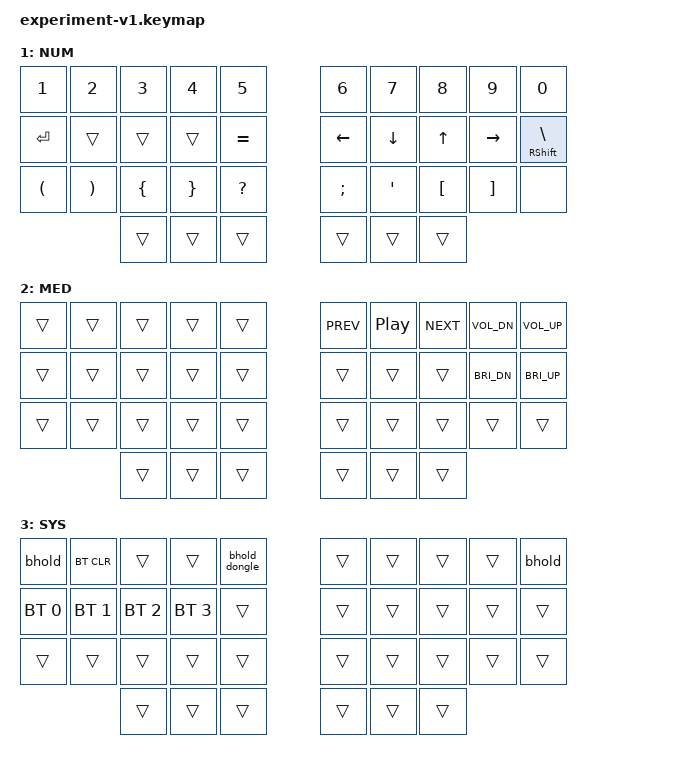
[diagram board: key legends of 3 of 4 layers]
#include <behaviors.dtsi>
#include <dt-bindings/zmk/keys.h>
#include <dt-bindings/zmk/bt.h>
#include <dt-bindings/zmk/outputs.h>

// Home row mods macro
#define HRML(k1,k2,k3,k4) &hml LSHFT k1 &hml LCTRL k2  &hml LALT k3  &hml LGUI k4
#define HRMR(k1,k2,k3,k4) &hmr RGUI k1  &hmr RALT k2  &hmr RCTRL k3  &hmr RSHFT k4

// Key positions for positional hold-tap, kept for reference. Currently unused:
// the homerow mods below deliberately do NOT use cross-hand gating (see the
// note on `hml`). This board is a TOTEMIST (36 keys), so these match the
// standard 36-key numbering -- see the matrix transform in
// config/boards/shields/totem/totem.dtsi:
//   Row 0:     0  1  2  3  4  |  5  6  7  8  9
//   Row 1:    10 11 12 13 14  | 15 16 17 18 19
//   Row 2:    20 21 22 23 24  | 25 26 27 28 29
//   Thumbs:      30 31 32     | 33 34 35
#define KEYS_L 0 1 2 3 4 10 11 12 13 14 20 21 22 23 24   // left-hand keys
#define KEYS_R 5 6 7 8 9 15 16 17 18 19 25 26 27 28 29   // right-hand keys
#define THUMBS 30 31 32 33 34 35                         // thumb keys

#define L0 0
#define L1 1
#define L2 2
#define L3 3

// Layer-tap, used by the left Enter/L1 and right Space/L1 thumbs.
//
// ZMK's stock `&lt` is `tap-preferred`, which only resolves a hold when the
// tapping term expires -- pressing and releasing another key while it is held
// does NOT trigger the hold. So a quick layer chord (hold the thumb, tap a
// key, release) completed inside 200ms emits SPACE plus that key instead of
// the layer keycode. `balanced` resolves the hold as soon as another key is
// pressed and released, which is exactly what a layer chord looks like.
&lt {
    flavor = "balanced";
    tapping-term-ms = <175>;
    quick-tap-ms = <125>;
};

/ {
    behaviors {
        // Grave/Shift and Tab/Shift on the left; minus/GUI on the right.
        //
        // Deliberately has NO `global-quick-tap` / `require-prior-idle-ms`.
        // Those make ZMK resolve the key to an *instant tap* whenever any other
        // key was pressed within the preceding window, no matter how long or
        // how hard the key is then held -- see is_quick_tap() in ZMK's
        // behavior_hold_tap.c. Since Shift is nearly always pressed immediately
        // after typing a letter, that reliably emitted TAB instead of SHIFT.
        //
        // Prior-idle gating is right for homerow mods (see hml/hmr below), but
        // wrong for thumbs, which are never pressed accidentally while typing.
        ht: hold_tap {
            label = "hold_tap";
            compatible = "zmk,behavior-hold-tap";
            #binding-cells = <2>;
            flavor = "balanced";
            tapping-term-ms = <175>;
            quick-tap-ms = <125>;
            bindings = <&kp>, <&kp>;
        };

        // Homerow mods.
        //
        // These are split out from the thumb `ht` behavior so the two can be
        // tuned independently. Timing was 220ms / prior-idle 150ms; it is now
        // 190ms / 100ms to bias toward HOLD, since missed holds proved far
        // more common than false ones.
        //
        // NOTE: no `hold-trigger-key-positions` / `hold-trigger-on-release`.
        // Those implement urob's cross-hand ("timeless") positional hold-tap,
        // where a homerow mod can ONLY resolve as a hold if the next key is on
        // the opposite half. That gate has no timeout escape hatch: holding
        // LGUI (F) and pressing C -- both left hand -- can never become a hold,
        // so it emits "fc" no matter how long F is held. That breaks the entire
        // left-hand shortcut cluster (CMD/CTRL + Q W A S Z X C V) and every
        // left-hand capital via LSHFT on A, which is why the left half felt far
        // worse than the right.
        //
        // Trade-off: without positional gating, a fast same-hand roll starting
        // on the homerow ("as", "sad", "fad") can register a mod if it begins
        // after >100ms of idle time. If that becomes the more annoying failure
        // mode, re-add the two properties below (KEYS_R THUMBS for hml,
        // KEYS_L THUMBS for hmr) and use combos for same-hand shortcuts.
        hml: home_row_mod_left {
            label = "hrm_left";
            compatible = "zmk,behavior-hold-tap";
            #binding-cells = <2>;
            flavor = "balanced";
            tapping-term-ms = <190>;
            quick-tap-ms = <120>;
            require-prior-idle-ms = <100>;
            bindings = <&kp>, <&kp>;
        };

        hmr: home_row_mod_right {
            label = "hrm_right";
            compatible = "zmk,behavior-hold-tap";
            #binding-cells = <2>;
            flavor = "balanced";
            tapping-term-ms = <190>;
            quick-tap-ms = <120>;
            require-prior-idle-ms = <100>;
            bindings = <&kp>, <&kp>;
        };

        bhold: bootloader_hold {
            compatible = "zmk,behavior-long-press";
            #binding-cells = <0>;
            duration-ms = <2000>;
            bindings = <&bootloader>;
        };

        // Same 2s hold, retargeted at the split central via `central`. In
        // dongle mode that is the keyless USB dongle, which otherwise can only
        // reach its UF2 bootloader by opening its case. Standalone, the central
        // is the left half, so this just duplicates the left pinky hold.
        bhold_dongle: bootloader_hold_dongle {
            compatible = "zmk,behavior-long-press";
            #binding-cells = <0>;
            duration-ms = <2000>;
            bindings = <&bootloader>;
            central;
        };

        hyper_guard: hyper_guard {
            compatible = "zmk,behavior-hyper-guard";
            #binding-cells = <1>;
        };
    };

    combos {
        compatible = "zmk,combos";
        // Letter combos need both keys within 25ms (ZMK's default is 50ms), so
        // quick rolls while typing, like O then P, stay as plain letters.
        combo_esc_op {
            timeout-ms = <25>;
            key-positions = <8 9>;  // Combo o+p for ESCAPE
            bindings = <&kp ESC>;
        };
        combo_esc_qw {
            timeout-ms = <25>;
            key-positions = <0 1>;  // Combo q+w for ESCAPE
            bindings = <&kp ESC>;
        };
        combo_maintenance_layer {
            timeout-ms = <100>;
            key-positions = <30 35>;
            bindings = <&mo L3>;
            layers = <L0 L1 L2>;
        };
    };


    keymap {
        compatible = "zmk,keymap";

        // Position 29 is dead in hardware. Keep slash on the working right
        // home-row pinky and put Enter on L1+A and backslash on L1+slash.
        layer_zero {
            display-name = "ABC";
            bindings = <
        //             ╭───────────┬───────────┬───────────┬───────────┬───────────╮   ╭───────────┬───────────┬───────────┬───────────┬───────────╮
                       &kp Q       &kp W       &kp E       &kp R       &kp T           &kp Y       &kp U       &kp I       &kp O       &kp P
        //             ├───────────├───────────├───────────├───────────├───────────┤   ├───────────├───────────├───────────├───────────├───────────┤
                       HRML(A,         S,          D,          F)      &kp G           &kp H       HRMR(J,         K,          L,          FSLH)
        //             ├───────────├───────────├───────────├───────────├───────────┤   ├───────────├───────────├───────────├───────────├───────────┤
                       &kp Z       &kp X       &kp C       &kp V       &kp B           &kp N       &kp M       &kp COMMA   &hyper_guard DOT &none
        //             ╰───────────┴───────────┴───────────├───────────├───────────┤   ├───────────├───────────├───────────┴───────────┴───────────╯
                                             &ht LSHFT GRAVE &lt L1 RET &ht LSHFT TAB  &lt L1 SPACE  &kp BSPC   &ht RGUI MINUS
        //                                     ╰───────────┴───────────┴───────────╯   ╰───────────┴───────────┴───────────╯
            >;
        };


        layer_one {
            display-name = "NUM";
            bindings = <
        //             ╭───────────┬───────────┬───────────┬───────────┬───────────╮   ╭───────────┬───────────┬───────────┬───────────┬───────────╮
                       &kp N1      &kp N2      &kp N3      &kp N4      &kp N5          &kp N6      &kp N7      &kp N8      &kp N9      &kp N0
        //             ├───────────├───────────├───────────├───────────├───────────┤   ├───────────├───────────├───────────├───────────├───────────┤
                       &kp RET     &trans      &trans      &trans      &kp EQUAL       &kp LEFT    &kp DOWN    &kp UP      &kp RIGHT   &ht RSHFT BSLH
        //             ├───────────├───────────├───────────├───────────├───────────┤   ├───────────├───────────├───────────├───────────├───────────┤
                       &kp LPAR    &kp RPAR    &kp LBRC    &kp RBRC    &kp QMARK       &kp SEMI    &kp SQT     &kp LBKT    &kp RBKT    &none
        //             ╰───────────┴───────────┴───────────├───────────├───────────┤   ├───────────├───────────├───────────┴───────────┴───────────╯
                                               &trans      &trans      &trans          &trans      &trans      &trans
        //                                     ╰───────────┴───────────┴───────────╯   ╰───────────┴───────────┴───────────╯
            >;
        };



        layer_two {
            display-name = "MED";
            bindings = <
        //             ╭───────────┬───────────┬───────────┬───────────┬───────────╮   ╭───────────┬───────────┬───────────┬───────────┬───────────╮
                       &trans      &trans      &trans      &trans      &trans          &kp C_PREV  &kp C_PP    &kp C_NEXT  &kp C_VOL_DN   &kp C_VOL_UP
        //             ├───────────├───────────├───────────├───────────├───────────┤   ├───────────├───────────├───────────├───────────├───────────┤
                       &trans      &trans      &trans      &trans      &trans          &trans      &trans      &trans      &kp C_BRI_DN   &kp C_BRI_UP
        //             ├───────────├───────────├───────────├───────────├───────────┤   ├───────────├───────────├───────────├───────────├───────────┤
                       &trans      &trans      &trans      &trans      &trans          &trans      &trans      &trans      &trans      &trans
        //             ╰───────────┴───────────┴───────────├───────────├───────────┤   ├───────────├───────────├───────────┴───────────┴───────────╯
                                               &trans      &trans      &trans          &trans      &trans      &trans
        //                                     ╰───────────┴───────────┴───────────╯   ╰───────────┴───────────┴───────────╯
            >;
        };

        layer_three {
            display-name = "SYS";
            bindings = <
                       &bhold      &bt BT_CLR  &trans      &trans      &bhold_dongle   &trans      &trans      &trans      &trans      &bhold
                       &bt BT_SEL 0 &bt BT_SEL 1 &bt BT_SEL 2 &bt BT_SEL 3 &trans     &trans      &trans      &trans      &trans      &trans
                       &trans      &trans      &trans      &trans      &trans          &trans      &trans      &trans      &trans      &trans
                                               &trans      &trans      &trans          &trans      &trans      &trans
            >;
        };
    };
};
